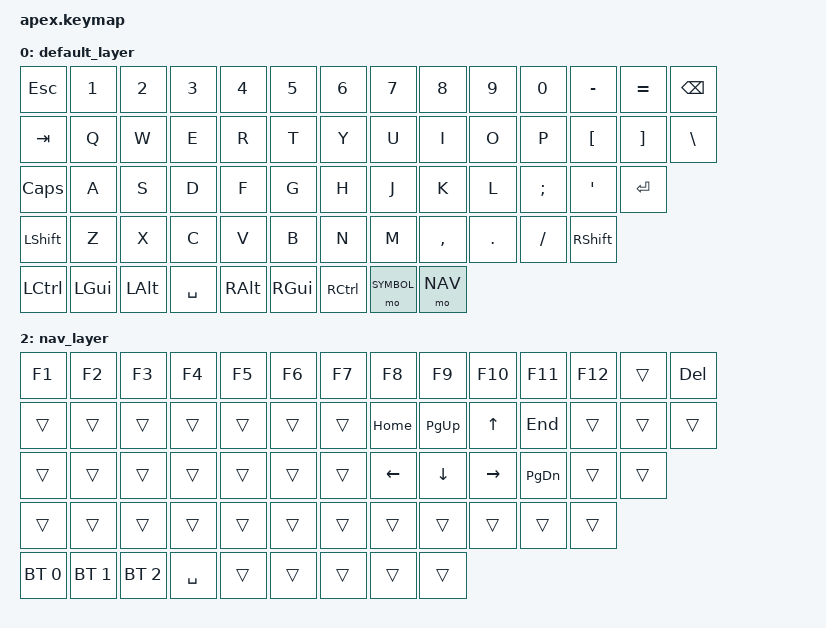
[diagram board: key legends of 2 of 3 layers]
#include <behaviors.dtsi>
#include <dt-bindings/zmk/keys.h>
#include <dt-bindings/zmk/bt.h>
#include <dt-bindings/zmk/rgb.h>
#include <dt-bindings/zmk/ext_power.h>
#include <dt-bindings/zmk/outputs.h>

#define DEFAULT 0
#define SYMBOL 1
#define NAV 2

/ {
    keymap {
        compatible = "zmk,keymap";

        default_layer {
            // ANSI 104-key skeleton.
            // This is intentionally a minimal working layout to define the structure.
            // Expand this into the full row/column map when the PCB matrix is finalized.
            bindings = <
                &kp ESC    &kp N1   &kp N2   &kp N3   &kp N4   &kp N5   &kp N6   &kp N7   &kp N8   &kp N9   &kp N0   &kp MINUS &kp EQUAL &kp BSPC
                &kp TAB    &kp Q    &kp W    &kp E    &kp R    &kp T    &kp Y    &kp U    &kp I    &kp O    &kp P    &kp LBKT  &kp RBKT  &kp BSLH
                &kp CAPS   &kp A    &kp S    &kp D    &kp F    &kp G    &kp H    &kp J    &kp K    &kp L    &kp SEMI &kp SQT   &kp ENTER
                &kp LSHFT  &kp Z    &kp X    &kp C    &kp V    &kp B    &kp N    &kp M    &kp COMMA &kp DOT &kp FSLH &kp RSHFT
                &kp LCTRL  &kp LGUI &kp LALT &kp SPACE &kp RALT &kp RGUI &kp RCTRL &mo SYMBOL &mo NAV
            >;

            sensor-bindings = <&inc_dec_kp C_VOL_UP C_VOL_DN>;
        };

        symbol_layer {
            bindings = <
                &kp GRAVE  &kp F1  &kp F2  &kp F3  &kp F4  &kp F5  &kp F6  &kp F7  &kp F8  &kp F9  &kp F10 &kp F11 &kp F12 &kp DEL
                &trans     &kp EXCL &kp AT &kp HASH &kp DLLR &kp PERCENT &kp CARET &kp AMPS &kp STAR &kp LPAR &kp RPAR &kp UNDER &kp PLUS &kp PIPE
                &trans     &kp LBRC &kp RBRC &kp COLON &kp SEMI &kp QMARK &kp DQT &kp APOS &kp TILDE &kp MINUS &kp EQUAL &kp ENTER
                &trans     &kp BSLH &kp FSLH &kp COMMA &kp DOT &kp LT &kp GT &kp PLUS &kp MINUS &kp STAR &kp SLASH &trans
                &bt BT_CLR &trans &trans &trans &trans &trans &trans &trans &trans
            >;
        };

        nav_layer {
            bindings = <
                &kp F1  &kp F2  &kp F3  &kp F4  &kp F5  &kp F6  &kp F7  &kp F8  &kp F9  &kp F10 &kp F11 &kp F12 &trans &kp DEL
                &trans  &trans &trans &trans &trans &trans &trans &kp HOME &kp PG_UP &kp UP &kp END &trans &trans &trans
                &trans  &trans &trans &trans &trans &trans &trans &kp LEFT &kp DOWN &kp RIGHT &kp PG_DN &trans &trans
                &trans  &trans &trans &trans &trans &trans &trans &trans &trans &trans &trans &trans
                &bt BT_SEL 0 &bt BT_SEL 1 &bt BT_SEL 2 &kp SPACE &trans &trans &trans &trans &trans
            >;
        };
    };
};
